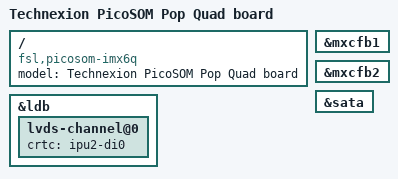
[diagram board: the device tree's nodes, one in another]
/*
 * Copyright 2015 Technexion Ltd.
 *
 * Author: Richard Hu <richard.hu@technexion.com>
 *
 * This program is free software; you can redistribute it and/or modify
 * it under the terms of the GNU General Public License version 2 as
 * published by the Free Software Foundation.
 *
 */
/dts-v1/;

#include <dt-bindings/interrupt-controller/irq.h>
#include "imx6q.dtsi"
#include "imx6qdl-picosom.dtsi"

/ {
	model = "Technexion PicoSOM Pop Quad board";
	compatible = "fsl,picosom-imx6q", "fsl,imx6q";
};

&ldb {
	lvds-channel@0 {
		crtc = "ipu2-di0";
	};
};

&mxcfb1 {
	status = "okay";
};

&mxcfb2 {
	status = "okay";
};

&sata {
	status = "okay";
};
